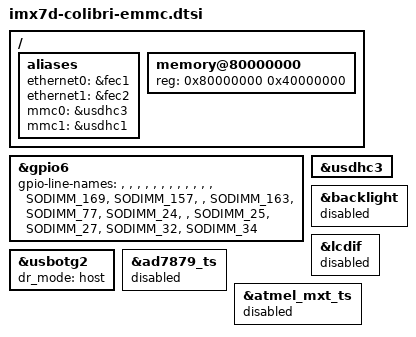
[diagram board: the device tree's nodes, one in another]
// SPDX-License-Identifier: GPL-2.0 OR MIT
/*
 * Copyright 2017-2021 Toradex
 */

#include "imx7d.dtsi"
#include "imx7-colibri.dtsi"

/ {
	aliases {
		/* add ethernet aliases which is required to proprely pass mac
		   address from bootloader. Also with the update to 5.4.70-2.3.0
		   the kernel hangs without these aliases.
		 */
		ethernet0 = &fec1;
		ethernet1 = &fec2;
		/* the following, together with kernel patches, forces a fixed assignment
		   between device id and usdhc controller */
		/* i.e. the eMMC on usdhc3 will be /dev/mmcblk0 */
		mmc0 = &usdhc3; /* eMMC */
		mmc1 = &usdhc1; /* MMC 4bit slot */
	};

	memory@80000000 {
		device_type = "memory";
		reg = <0x80000000 0x40000000>;
	};
};

&gpio6 {
	gpio-line-names = "",
			  "",
			  "",
			  "",
			  "",
			  "",
			  "",
			  "",
			  "",
			  "",
			  "",
			  "",
			  "SODIMM_169",
			  "SODIMM_157",
			  "",
			  "SODIMM_163",
			  "SODIMM_77",
			  "SODIMM_24",
			  "",
			  "SODIMM_25",
			  "SODIMM_27",
			  "SODIMM_32",
			  "SODIMM_34";
};

&usbotg2 {
	dr_mode = "host";
};

&usdhc3 {
	status = "okay";
};

&ad7879_ts {
	status = "disabled";
};

&backlight {
	status = "disabled";
};

&lcdif {
	status = "disabled";
};

&atmel_mxt_ts {
	status = "disabled";
};
